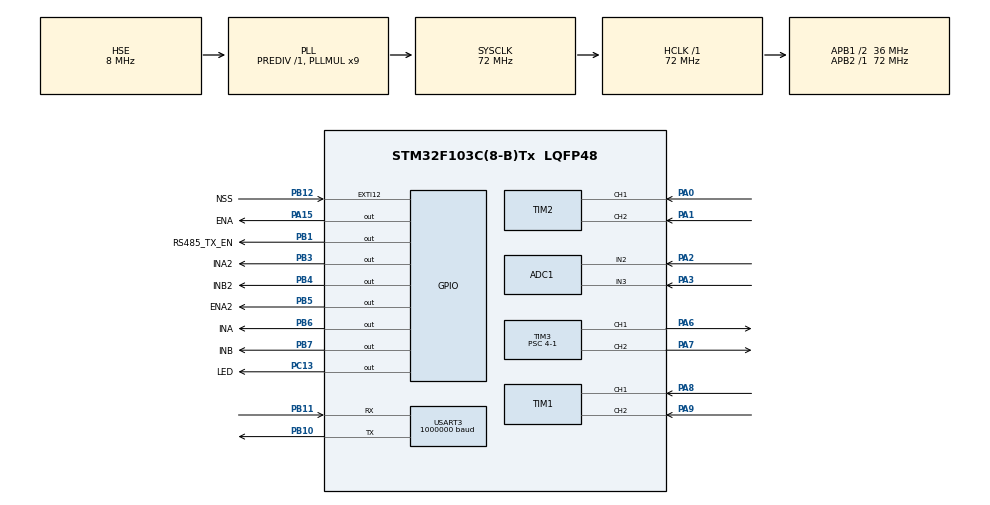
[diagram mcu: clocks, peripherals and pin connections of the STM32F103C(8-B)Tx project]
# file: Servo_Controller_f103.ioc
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ADC1.Channel-1\#ChannelRegularConversion=ADC_CHANNEL_2
ADC1.Channel-2\#ChannelRegularConversion=ADC_CHANNEL_3
ADC1.EnableRegularConversion=ENABLE
ADC1.ExternalTrigConv=ADC_EXTERNALTRIGCONV_T3_TRGO
ADC1.NbrOfConversion=2
ADC1.NbrOfConversionFlag=1
ADC1.Rank-1\#ChannelRegularConversion=1
ADC1.Rank-2\#ChannelRegularConversion=2
ADC1.SamplingTime-1\#ChannelRegularConversion=ADC_SAMPLETIME_239CYCLES_5
ADC1.SamplingTime-2\#ChannelRegularConversion=ADC_SAMPLETIME_239CYCLES_5
ADC1.master=1
Dma.ADC1.0.Direction=DMA_PERIPH_TO_MEMORY
Dma.ADC1.0.Instance=DMA1_Channel1
Dma.ADC1.0.MemDataAlignment=DMA_MDATAALIGN_HALFWORD
Dma.ADC1.0.MemInc=DMA_MINC_ENABLE
Dma.ADC1.0.Mode=DMA_CIRCULAR
Dma.ADC1.0.PeriphDataAlignment=DMA_PDATAALIGN_HALFWORD
Dma.ADC1.0.PeriphInc=DMA_PINC_DISABLE
Dma.ADC1.0.Priority=DMA_PRIORITY_MEDIUM
Dma.Request0=ADC1
Dma.Request1=USART3_RX
Dma.Request2=USART3_TX
Dma.USART3_RX.1.Direction=DMA_PERIPH_TO_MEMORY
Dma.USART3_RX.1.Instance=DMA1_Channel3
Dma.USART3_RX.1.MemDataAlignment=DMA_MDATAALIGN_BYTE
Dma.USART3_RX.1.MemInc=DMA_MINC_ENABLE
Dma.USART3_RX.1.Mode=DMA_NORMAL
Dma.USART3_RX.1.PeriphDataAlignment=DMA_PDATAALIGN_BYTE
Dma.USART3_RX.1.PeriphInc=DMA_PINC_DISABLE
Dma.USART3_RX.1.Priority=DMA_PRIORITY_HIGH
Dma.USART3_TX.2.Direction=DMA_MEMORY_TO_PERIPH
Dma.USART3_TX.2.Instance=DMA1_Channel2
Dma.USART3_TX.2.MemDataAlignment=DMA_MDATAALIGN_BYTE
Dma.USART3_TX.2.MemInc=DMA_MINC_ENABLE
Dma.USART3_TX.2.Mode=DMA_NORMAL
Dma.USART3_TX.2.PeriphDataAlignment=DMA_PDATAALIGN_BYTE
Dma.USART3_TX.2.PeriphInc=DMA_PINC_DISABLE
Dma.USART3_TX.2.Priority=DMA_PRIORITY_HIGH
Mcu.Family=STM32F1
Mcu.Name=STM32F103C(8-B)Tx
Mcu.Package=LQFP48
NVIC.DMA1_Channel1_IRQn=true\:0\:0\:false\:false\:true\:false\:true\:true
NVIC.DMA1_Channel2_IRQn=true\:0\:0\:false\:false\:true\:false\:true\:true
NVIC.DMA1_Channel3_IRQn=true\:0\:0\:false\:false\:true\:false\:true\:true
NVIC.EXTI15_10_IRQn=true\:0\:0\:false\:false\:true\:true\:true\:true
NVIC.PriorityGroup=NVIC_PRIORITYGROUP_4
NVIC.TIM3_IRQn=true\:1\:0\:true\:false\:true\:true\:true\:true
NVIC.USART3_IRQn=true\:0\:0\:false\:false\:true\:true\:true\:true
PA0-WKUP.Signal=S_TIM2_CH1_ETR
PA1.Signal=S_TIM2_CH2
PA13.Mode=Serial_Wire
PA13.Signal=SYS_JTMS-SWDIO
PA14.Mode=Serial_Wire
PA14.Signal=SYS_JTCK-SWCLK
PA15.GPIO_Label=ENA
PA15.GPIO_ModeDefaultOutputPP=GPIO_MODE_OUTPUT_PP
PA15.GPIO_PuPd=GPIO_PULLDOWN
PA15.Signal=GPIO_Output
PA2.Signal=ADCx_IN2
PA3.Signal=ADCx_IN3
PA6.Signal=S_TIM3_CH1
PA7.Signal=S_TIM3_CH2
PA8.Signal=S_TIM1_CH1
PA9.Signal=S_TIM1_CH2
PB1.GPIO_Label=RS485_TX_EN
PB1.GPIO_Speed=GPIO_SPEED_FREQ_HIGH
PB1.PinState=GPIO_PIN_RESET
PB1.Signal=GPIO_Output
PB10.Mode=Asynchronous
PB10.Signal=USART3_TX
PB11.Mode=Asynchronous
PB11.Signal=USART3_RX
PB12.GPIO_Label=NSS
PB12.GPIO_ModeDefaultEXTI=GPIO_MODE_IT_RISING_FALLING
PB12.Signal=GPXTI12
PB3.GPIO_Label=INA2
PB3.GPIO_PuPd=GPIO_PULLDOWN
PB3.Signal=GPIO_Output
PB4.GPIO_Label=INB2
PB4.Signal=GPIO_Output
PB5.GPIO_Label=ENA2
PB5.Signal=GPIO_Output
PB6.GPIO_Label=INA
PB6.Signal=GPIO_Output
PB7.GPIO_Label=INB
PB7.Signal=GPIO_Output
PC13-TAMPER-RTC.GPIO_Label=LED
PC13-TAMPER-RTC.Signal=GPIO_Output
PD0-OSC_IN.Mode=HSE-External-Oscillator
PD0-OSC_IN.Signal=RCC_OSC_IN
PD1-OSC_OUT.Mode=HSE-External-Oscillator
PD1-OSC_OUT.Signal=RCC_OSC_OUT
ProjectManager.HeapSize=0x200
ProjectManager.StackSize=0x400
ProjectManager.TargetToolchain=Makefile
RCC.ADCPresc=RCC_ADCPCLK2_DIV6
RCC.AHBFreq_Value=72000000
RCC.APB1CLKDivider=RCC_HCLK_DIV2
RCC.APB1Freq_Value=36000000
RCC.APB1TimFreq_Value=72000000
RCC.APB2Freq_Value=72000000
RCC.APB2TimFreq_Value=72000000
RCC.HCLKFreq_Value=72000000
RCC.PLLMUL=RCC_PLL_MUL9
RCC.PLLSourceVirtual=RCC_PLLSOURCE_HSE
RCC.SYSCLKFreq_VALUE=72000000
RCC.SYSCLKSource=RCC_SYSCLKSOURCE_PLLCLK
RCC.USBFreq_Value=72000000
SH.ADCx_IN2.0=ADC1_IN2,IN2
SH.ADCx_IN3.0=ADC1_IN3,IN3
SH.S_TIM1_CH1.0=TIM1_CH1,Encoder_Interface
SH.S_TIM1_CH2.0=TIM1_CH2,Encoder_Interface
SH.S_TIM2_CH1_ETR.0=TIM2_CH1,Encoder_Interface
SH.S_TIM2_CH2.0=TIM2_CH2,Encoder_Interface
SH.S_TIM3_CH1.0=TIM3_CH1,PWM Generation1 CH1
SH.S_TIM3_CH2.0=TIM3_CH2,PWM Generation2 CH2
TIM1.EncoderMode=TIM_ENCODERMODE_TI12
TIM1.IC1Filter=15
TIM1.IC2Filter=15
TIM2.EncoderMode=TIM_ENCODERMODE_TI12
TIM2.IC1Filter=15
TIM2.IC2Filter=15
TIM3.Channel-PWM\ Generation1\ CH1=TIM_CHANNEL_1
TIM3.Channel-PWM\ Generation2\ CH2=TIM_CHANNEL_2
TIM3.Period=1000-1
TIM3.Prescaler=4-1
TIM3.TIM_MasterOutputTrigger=TIM_TRGO_UPDATE
USART3.BaudRate=1000000
USART3.VirtualMode=VM_ASYNC
board=custom

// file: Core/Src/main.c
/* USER CODE BEGIN Header */
/**
 ******************************************************************************
 * @file           : main.c
 * @brief          : Main program body
 ******************************************************************************
 * @attention
 *
 * Copyright (c) 2023 STMicroelectronics.
 * All rights reserved.
 *
 * This software is licensed under terms that can be found in the LICENSE file
 * in the root directory of this software component.
 * If no LICENSE file comes with this software, it is provided AS-IS.
 *
 ******************************************************************************
 */
/* USER CODE END Header */
#include "main.h"
#include "adc.h"
#include "dma.h"
#include "tim.h"
#include "usart.h"
#include "gpio.h"

/* USER CODE BEGIN Includes */
#include "IQmathLib.h"
#include "main_init.h"
#include "potamon_bus_lowlvl_handle.h"
/* USER CODE END Includes */

/* USER CODE BEGIN PV */
uint8_t servo1_debug_mode;
uint8_t servo2_debug_mode;

float s1_set_cur, s1_set_vel;
float s2_set_cur, s2_set_vel;

servo_iq18_t servo1_g, servo2_g;

/* USER CODE END PV */

void SystemClock_Config(void);

int main(void)
{

  /* MCU Configuration--------------------------------------------------------*/

  /* Reset of all peripherals, Initializes the Flash interface and the Systick. */
  HAL_Init();

  /* Configure the system clock */
  SystemClock_Config();

  /* Initialize all configured peripherals */
  MX_GPIO_Init();
  MX_DMA_Init();
  MX_TIM1_Init();
  MX_TIM2_Init();
  MX_TIM3_Init();
  MX_ADC1_Init();
  MX_USART3_UART_Init();
  /* USER CODE BEGIN 2 */

  init_mtr_ctrl(); // Initializes all peripherals and structures needed for motor control

  /* USER CODE END 2 */

  /* Infinite loop */
  /* USER CODE BEGIN WHILE */
  while (1)
  {

    // switch (servo1_debug_mode)
    // {
    // case 0:
    //   servo_iq18_controlCurrent(&servo1_g, s1_set_cur);
    //   break;
    // case 1:
    //   servo_iq18_controlVelocity(&servo1_g, s1_set_vel);
    //   break;
    // default:
    //   break;
    // }

    // switch (servo2_debug_mode)
    // {
    // case 0:
    //   servo_iq18_controlCurrent(&servo2_g, s2_set_cur);
    //   break;
    // case 1:
    //   servo_iq18_controlVelocity(&servo2_g, s2_set_vel);
    //   break;
    // default:
    //   break;
    // }

    /* USER CODE END WHILE */

  }
}

void SystemClock_Config(void)
{
  RCC_OscInitTypeDef RCC_OscInitStruct = {0};
  RCC_ClkInitTypeDef RCC_ClkInitStruct = {0};
  RCC_PeriphCLKInitTypeDef PeriphClkInit = {0};

  /** Initializes the RCC Oscillators according to the specified parameters
  * in the RCC_OscInitTypeDef structure.
  */
  RCC_OscInitStruct.OscillatorType = RCC_OSCILLATORTYPE_HSE;
  RCC_OscInitStruct.HSEState = RCC_HSE_ON;
  RCC_OscInitStruct.HSEPredivValue = RCC_HSE_PREDIV_DIV1;
  RCC_OscInitStruct.HSIState = RCC_HSI_ON;
  RCC_OscInitStruct.PLL.PLLState = RCC_PLL_ON;
  RCC_OscInitStruct.PLL.PLLSource = RCC_PLLSOURCE_HSE;
  RCC_OscInitStruct.PLL.PLLMUL = RCC_PLL_MUL9;
  if (HAL_RCC_OscConfig(&RCC_OscInitStruct) != HAL_OK)
  {
    Error_Handler();
  }

  /** Initializes the CPU, AHB and APB buses clocks
  */
  RCC_ClkInitStruct.ClockType = RCC_CLOCKTYPE_HCLK|RCC_CLOCKTYPE_SYSCLK
                              |RCC_CLOCKTYPE_PCLK1|RCC_CLOCKTYPE_PCLK2;
  RCC_ClkInitStruct.SYSCLKSource = RCC_SYSCLKSOURCE_PLLCLK;
  RCC_ClkInitStruct.AHBCLKDivider = RCC_SYSCLK_DIV1;
  RCC_ClkInitStruct.APB1CLKDivider = RCC_HCLK_DIV2;
  RCC_ClkInitStruct.APB2CLKDivider = RCC_HCLK_DIV1;

  if (HAL_RCC_ClockConfig(&RCC_ClkInitStruct, FLASH_LATENCY_2) != HAL_OK)
  {
    Error_Handler();
  }
  PeriphClkInit.PeriphClockSelection = RCC_PERIPHCLK_ADC;
  PeriphClkInit.AdcClockSelection = RCC_ADCPCLK2_DIV6;
  if (HAL_RCCEx_PeriphCLKConfig(&PeriphClkInit) != HAL_OK)
  {
    Error_Handler();
  }
}

void Error_Handler(void)
{
  __disable_irq();
  while (1)
  {
  }
}
